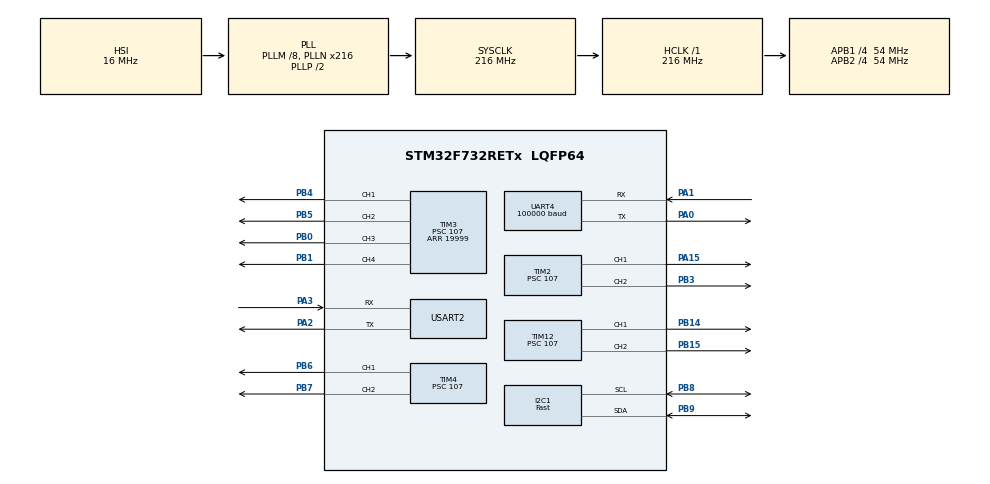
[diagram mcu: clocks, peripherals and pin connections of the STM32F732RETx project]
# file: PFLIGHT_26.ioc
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CORTEX_M7.default_mode_Activation=1
Dma.Request0=USART2_RX
Dma.Request1=UART4_RX
Dma.UART4_RX.1.Direction=DMA_PERIPH_TO_MEMORY
Dma.UART4_RX.1.FIFOMode=DMA_FIFOMODE_DISABLE
Dma.UART4_RX.1.Instance=DMA1_Stream2
Dma.UART4_RX.1.MemDataAlignment=DMA_MDATAALIGN_BYTE
Dma.UART4_RX.1.MemInc=DMA_MINC_ENABLE
Dma.UART4_RX.1.Mode=DMA_NORMAL
Dma.UART4_RX.1.PeriphDataAlignment=DMA_PDATAALIGN_BYTE
Dma.UART4_RX.1.PeriphInc=DMA_PINC_DISABLE
Dma.UART4_RX.1.Priority=DMA_PRIORITY_VERY_HIGH
Dma.USART2_RX.0.Direction=DMA_PERIPH_TO_MEMORY
Dma.USART2_RX.0.FIFOMode=DMA_FIFOMODE_DISABLE
Dma.USART2_RX.0.Instance=DMA1_Stream5
Dma.USART2_RX.0.MemDataAlignment=DMA_MDATAALIGN_BYTE
Dma.USART2_RX.0.MemInc=DMA_MINC_ENABLE
Dma.USART2_RX.0.Mode=DMA_NORMAL
Dma.USART2_RX.0.PeriphDataAlignment=DMA_PDATAALIGN_BYTE
Dma.USART2_RX.0.PeriphInc=DMA_PINC_DISABLE
Dma.USART2_RX.0.Priority=DMA_PRIORITY_VERY_HIGH
I2C1.I2C_Speed_Mode=I2C_Fast
I2C1.Timing=0x6000030D
Mcu.Family=STM32F7
Mcu.Name=STM32F732RETx
Mcu.Package=LQFP64
NVIC.DMA1_Stream2_IRQn=true\:0\:0\:false\:false\:true\:false\:true\:true
NVIC.DMA1_Stream5_IRQn=true\:0\:0\:false\:false\:true\:false\:true\:true
NVIC.PriorityGroup=NVIC_PRIORITYGROUP_4
PA0-WKUP.Mode=Asynchronous
PA0-WKUP.Signal=UART4_TX
PA1.Mode=Asynchronous
PA1.Signal=UART4_RX
PA15.Signal=S_TIM2_CH1_ETR
PA2.Mode=Asynchronous
PA2.Signal=USART2_TX
PA3.Mode=Asynchronous
PA3.Signal=USART2_RX
PB0.Signal=S_TIM3_CH3
PB1.Signal=S_TIM3_CH4
PB14.Signal=S_TIM12_CH1
PB15.Signal=S_TIM12_CH2
PB3.Signal=S_TIM2_CH2
PB4.Signal=S_TIM3_CH1
PB5.Signal=S_TIM3_CH2
PB6.Signal=S_TIM4_CH1
PB7.Signal=S_TIM4_CH2
PB8.GPIO_Pu=GPIO_PULLUP
PB8.Mode=I2C
PB8.Signal=I2C1_SCL
PB9.GPIO_Pu=GPIO_PULLUP
PB9.Mode=I2C
PB9.Signal=I2C1_SDA
ProjectManager.HeapSize=0x200
ProjectManager.StackSize=0x400
ProjectManager.TargetToolchain=STM32CubeIDE
RCC.AHBFreq_Value=216000000
RCC.APB1CLKDivider=RCC_HCLK_DIV4
RCC.APB1Freq_Value=54000000
RCC.APB1TimFreq_Value=108000000
RCC.APB2CLKDivider=RCC_HCLK_DIV4
RCC.APB2Freq_Value=54000000
RCC.APB2TimFreq_Value=108000000
RCC.CortexFreq_Value=216000000
RCC.HCLKFreq_Value=216000000
RCC.HSE_VALUE=25000000
RCC.HSI_VALUE=16000000
RCC.LSE_VALUE=32768
RCC.PLLM=8
RCC.PLLN=216
RCC.SYSCLKFreq_VALUE=216000000
RCC.SYSCLKSource=RCC_SYSCLKSOURCE_PLLCLK
RCC.USBFreq_Value=216000000
RCC.VCOOutputFreq_Value=432000000
SH.S_TIM12_CH1.0=TIM12_CH1,PWM Generation1 CH1
SH.S_TIM12_CH2.0=TIM12_CH2,PWM Generation2 CH2
SH.S_TIM2_CH1_ETR.0=TIM2_CH1,PWM Generation1 CH1
SH.S_TIM2_CH2.0=TIM2_CH2,PWM Generation2 CH2
SH.S_TIM3_CH1.0=TIM3_CH1,PWM Generation1 CH1
SH.S_TIM3_CH2.0=TIM3_CH2,PWM Generation2 CH2
SH.S_TIM3_CH3.0=TIM3_CH3,PWM Generation3 CH3
SH.S_TIM3_CH4.0=TIM3_CH4,PWM Generation4 CH4
SH.S_TIM4_CH1.0=TIM4_CH1,PWM Generation1 CH1
SH.S_TIM4_CH2.0=TIM4_CH2,PWM Generation2 CH2
TIM12.Channel-PWM\ Generation1\ CH1=TIM_CHANNEL_1
TIM12.Channel-PWM\ Generation2\ CH2=TIM_CHANNEL_2
TIM12.Period=19999
TIM12.Prescaler=107
TIM2.Channel-PWM\ Generation1\ CH1=TIM_CHANNEL_1
TIM2.Channel-PWM\ Generation2\ CH2=TIM_CHANNEL_2
TIM2.Period=19999
TIM2.Prescaler=107
TIM3.Channel-PWM\ Generation1\ CH1=TIM_CHANNEL_1
TIM3.Channel-PWM\ Generation2\ CH2=TIM_CHANNEL_2
TIM3.Channel-PWM\ Generation3\ CH3=TIM_CHANNEL_3
TIM3.Channel-PWM\ Generation4\ CH4=TIM_CHANNEL_4
TIM3.Period=19999
TIM3.Prescaler=107
TIM4.Channel-PWM\ Generation1\ CH1=TIM_CHANNEL_1
TIM4.Channel-PWM\ Generation2\ CH2=TIM_CHANNEL_2
TIM4.Period=19999
TIM4.Prescaler=107
UART4.BaudRate=100000
UART4.Parity=PARITY_EVEN
UART4.RxPinLevelInvertParam=UART_ADVFEATURE_RXINV_ENABLE
UART4.StopBits=UART_STOPBITS_2
UART4.WordLength=WORDLENGTH_9B
USART2.VirtualMode-Asynchronous=VM_ASYNC
board=custom

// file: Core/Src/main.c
/* USER CODE BEGIN Header */
/**
  ******************************************************************************
  * @file           : main.c
  * @brief          : Main program body
  ******************************************************************************
  * @attention
  *
  * Copyright (c) 2026 STMicroelectronics.
  * All rights reserved.
  *
  * This software is licensed under terms that can be found in the LICENSE file
  * in the root directory of this software component.
  * If no LICENSE file comes with this software, it is provided AS-IS.
  *
  ******************************************************************************
  */
/* USER CODE END Header */
#include "main.h"
#include "dma.h"
#include "i2c.h"
#include "tim.h"
#include "usart.h"
#include "gpio.h"

/* USER CODE BEGIN Includes */
#include "wrapper.hpp"
#include "stdio.h"
/* USER CODE END Includes */

void SystemClock_Config(void);
static void MPU_Config(void);

/* USER CODE BEGIN 0 */
int __io_putchar(int ch){
	HAL_UART_Transmit(&huart2, (uint8_t *)&ch,1,100);
	return ch;
}
/* USER CODE END 0 */

int main(void)
{

  /* MPU Configuration--------------------------------------------------------*/
  MPU_Config();

  /* MCU Configuration--------------------------------------------------------*/

  /* Reset of all peripherals, Initializes the Flash interface and the Systick. */
  HAL_Init();

  /* Configure the system clock */
  SystemClock_Config();

  /* Initialize all configured peripherals */
  MX_GPIO_Init();
  MX_DMA_Init();
  MX_USART2_UART_Init();
  MX_I2C1_Init();
  MX_TIM12_Init();
  MX_TIM3_Init();
  MX_UART4_Init();
  MX_TIM4_Init();
  MX_TIM2_Init();
  /* USER CODE BEGIN 2 */

  // bulid check code
  printf("[main.c] program start bulid: 2\n");
  HAL_GPIO_WritePin(GPIOA, GPIO_PIN_1, GPIO_PIN_SET);

  // init code
  init();
  /* USER CODE END 2 */

  /* Infinite loop */
  while (1)
  {

    /* USER CODE BEGIN 3 */
	  loop();
  }
  /* USER CODE END 3 */
}

void SystemClock_Config(void)
{
  RCC_OscInitTypeDef RCC_OscInitStruct = {0};
  RCC_ClkInitTypeDef RCC_ClkInitStruct = {0};

  /** Configure the main internal regulator output voltage
  */
  __HAL_RCC_PWR_CLK_ENABLE();
  __HAL_PWR_VOLTAGESCALING_CONFIG(PWR_REGULATOR_VOLTAGE_SCALE1);

  /** Initializes the RCC Oscillators according to the specified parameters
  * in the RCC_OscInitTypeDef structure.
  */
  RCC_OscInitStruct.OscillatorType = RCC_OSCILLATORTYPE_HSI;
  RCC_OscInitStruct.HSIState = RCC_HSI_ON;
  RCC_OscInitStruct.HSICalibrationValue = RCC_HSICALIBRATION_DEFAULT;
  RCC_OscInitStruct.PLL.PLLState = RCC_PLL_ON;
  RCC_OscInitStruct.PLL.PLLSource = RCC_PLLSOURCE_HSI;
  RCC_OscInitStruct.PLL.PLLM = 8;
  RCC_OscInitStruct.PLL.PLLN = 216;
  RCC_OscInitStruct.PLL.PLLP = RCC_PLLP_DIV2;
  RCC_OscInitStruct.PLL.PLLQ = 2;
  if (HAL_RCC_OscConfig(&RCC_OscInitStruct) != HAL_OK)
  {
    Error_Handler();
  }

  /** Activate the Over-Drive mode
  */
  if (HAL_PWREx_EnableOverDrive() != HAL_OK)
  {
    Error_Handler();
  }

  /** Initializes the CPU, AHB and APB buses clocks
  */
  RCC_ClkInitStruct.ClockType = RCC_CLOCKTYPE_HCLK|RCC_CLOCKTYPE_SYSCLK
                              |RCC_CLOCKTYPE_PCLK1|RCC_CLOCKTYPE_PCLK2;
  RCC_ClkInitStruct.SYSCLKSource = RCC_SYSCLKSOURCE_PLLCLK;
  RCC_ClkInitStruct.AHBCLKDivider = RCC_SYSCLK_DIV1;
  RCC_ClkInitStruct.APB1CLKDivider = RCC_HCLK_DIV4;
  RCC_ClkInitStruct.APB2CLKDivider = RCC_HCLK_DIV4;

  if (HAL_RCC_ClockConfig(&RCC_ClkInitStruct, FLASH_LATENCY_7) != HAL_OK)
  {
    Error_Handler();
  }
}

 /* MPU Configuration */

void MPU_Config(void)
{
  MPU_Region_InitTypeDef MPU_InitStruct = {0};

  /* Disables the MPU */
  HAL_MPU_Disable();

  /** Initializes and configures the Region and the memory to be protected
  */
  MPU_InitStruct.Enable = MPU_REGION_ENABLE;
  MPU_InitStruct.Number = MPU_REGION_NUMBER0;
  MPU_InitStruct.BaseAddress = 0x0;
  MPU_InitStruct.Size = MPU_REGION_SIZE_4GB;
  MPU_InitStruct.SubRegionDisable = 0x87;
  MPU_InitStruct.TypeExtField = MPU_TEX_LEVEL0;
  MPU_InitStruct.AccessPermission = MPU_REGION_NO_ACCESS;
  MPU_InitStruct.DisableExec = MPU_INSTRUCTION_ACCESS_DISABLE;
  MPU_InitStruct.IsShareable = MPU_ACCESS_SHAREABLE;
  MPU_InitStruct.IsCacheable = MPU_ACCESS_NOT_CACHEABLE;
  MPU_InitStruct.IsBufferable = MPU_ACCESS_NOT_BUFFERABLE;

  HAL_MPU_ConfigRegion(&MPU_InitStruct);
  /* Enables the MPU */
  HAL_MPU_Enable(MPU_PRIVILEGED_DEFAULT);

}

void Error_Handler(void)
{
  __disable_irq();
  while (1)
  {
  }
}
